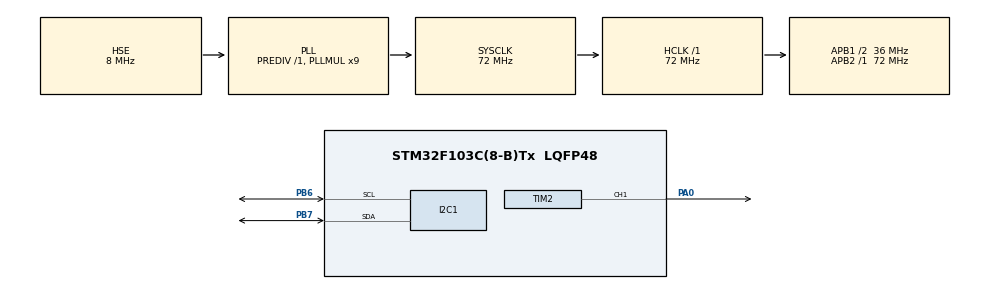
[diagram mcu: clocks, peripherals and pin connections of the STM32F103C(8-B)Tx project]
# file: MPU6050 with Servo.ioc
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Mcu.Family=STM32F1
Mcu.Name=STM32F103C(8-B)Tx
Mcu.Package=LQFP48
NVIC.PriorityGroup=NVIC_PRIORITYGROUP_4
NVIC.TIM1_UP_IRQn=true\:0\:0\:false\:false\:true\:true\:true\:true
NVIC.TIM2_IRQn=true\:0\:0\:false\:false\:true\:true\:true\:true
PA0-WKUP.Signal=S_TIM2_CH1_ETR
PA13.Mode=Serial_Wire
PA13.Signal=SYS_JTMS-SWDIO
PA14.Mode=Serial_Wire
PA14.Signal=SYS_JTCK-SWCLK
PB6.Mode=I2C
PB6.Signal=I2C1_SCL
PB7.Mode=I2C
PB7.Signal=I2C1_SDA
PD0-OSC_IN.Mode=HSE-External-Oscillator
PD0-OSC_IN.Signal=RCC_OSC_IN
PD1-OSC_OUT.Mode=HSE-External-Oscillator
PD1-OSC_OUT.Signal=RCC_OSC_OUT
ProjectManager.HeapSize=0x200
ProjectManager.StackSize=0x400
ProjectManager.TargetToolchain=MDK-ARM V5.32
RCC.AHBFreq_Value=72000000
RCC.APB1CLKDivider=RCC_HCLK_DIV2
RCC.APB1Freq_Value=36000000
RCC.APB1TimFreq_Value=72000000
RCC.APB2Freq_Value=72000000
RCC.APB2TimFreq_Value=72000000
RCC.HCLKFreq_Value=72000000
RCC.PLLMUL=RCC_PLL_MUL9
RCC.PLLSourceVirtual=RCC_PLLSOURCE_HSE
RCC.SYSCLKFreq_VALUE=72000000
RCC.SYSCLKSource=RCC_SYSCLKSOURCE_PLLCLK
RCC.USBFreq_Value=72000000
SH.S_TIM2_CH1_ETR.0=TIM2_CH1,PWM Generation1 CH1
TIM1.AutoReloadPreload=TIM_AUTORELOAD_PRELOAD_ENABLE
TIM1.Period=1999
TIM1.Prescaler=35999
TIM2.AutoReloadPreload=TIM_AUTORELOAD_PRELOAD_ENABLE
TIM2.Channel-PWM\ Generation1\ CH1=TIM_CHANNEL_1
TIM2.Period=799
TIM2.Prescaler=1799
VP_TIM1_VS_ClockSourceINT.Mode=Internal
board=custom

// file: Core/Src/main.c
/* USER CODE BEGIN Header */
/**
  ******************************************************************************
  * @file           : main.c
  * @brief          : Main program body
  ******************************************************************************
  * @attention
  *
  * Copyright (c) 2023 STMicroelectronics.
  * All rights reserved.
  *
  * This software is licensed under terms that can be found in the LICENSE file
  * in the root directory of this software component.
  * If no LICENSE file comes with this software, it is provided AS-IS.
  *
  ******************************************************************************
  */
/* USER CODE END Header */
#include "main.h"

/* USER CODE BEGIN Includes */
#include "sd_hal_mpu6050.h"
#include "stdint.h"
/* USER CODE END Includes */

/* USER CODE BEGIN PM */
void Servo_Angle(int angle);
void Servo_Angle2(int angle);
void MPU6050(I2C_HandleTypeDef *hi2c, SD_MPU6050 *mpu);
/* USER CODE END PM */

I2C_HandleTypeDef hi2c1;

TIM_HandleTypeDef htim1;
TIM_HandleTypeDef htim2;

/* USER CODE BEGIN PV */
SD_MPU6050 mpu1;

/* USER CODE END PV */

void SystemClock_Config(void);
static void MX_GPIO_Init(void);
static void MX_TIM1_Init(void);
static void MX_I2C1_Init(void);
static void MX_TIM2_Init(void);

/* USER CODE BEGIN 0 */
int counter = 0;
int G_angle =0;
float temp;
		int16_t a_x =0;
		int16_t a_y =0;
		int16_t a_z =0;
		int16_t Gyroscope_X = 0;
		int16_t Gyroscope_Y = 0;
		int16_t Gyroscope_Z = 0;
/* USER CODE END 0 */

int main(void)
{

  /* MCU Configuration--------------------------------------------------------*/

  /* Reset of all peripherals, Initializes the Flash interface and the Systick. */
  HAL_Init();

  /* Configure the system clock */
  SystemClock_Config();

  /* Initialize all configured peripherals */
  MX_GPIO_Init();
  MX_TIM1_Init();
  MX_I2C1_Init();
  MX_TIM2_Init();
  /* USER CODE BEGIN 2 */
	HAL_TIM_Base_Start_IT(&htim1);
	HAL_TIM_PWM_Start(&htim2,TIM_CHANNEL_1);
  /* USER CODE END 2 */

  /* Infinite loop */
  while (1)
  {

    /* USER CODE BEGIN 3 */
		if(counter%2 ==0)
		{MPU6050(&hi2c1,&mpu1);
		}

		G_angle = (a_x+20000)/300+9;
		HAL_TIM_PWM_Start(&htim2, TIM_CHANNEL_1);
		htim2.Instance -> CCR1 = G_angle;
		//Servo_Angle(G_angle);

		//Servo tim Prescaller = 1799, Counter = 799;
		//timer tim Prescaller = 35999, Counter = 1999;

  }
  /* USER CODE END 3 */
}

void SystemClock_Config(void)
{
  RCC_OscInitTypeDef RCC_OscInitStruct = {0};
  RCC_ClkInitTypeDef RCC_ClkInitStruct = {0};

  /** Initializes the RCC Oscillators according to the specified parameters
  * in the RCC_OscInitTypeDef structure.
  */
  RCC_OscInitStruct.OscillatorType = RCC_OSCILLATORTYPE_HSE;
  RCC_OscInitStruct.HSEState = RCC_HSE_ON;
  RCC_OscInitStruct.HSEPredivValue = RCC_HSE_PREDIV_DIV1;
  RCC_OscInitStruct.HSIState = RCC_HSI_ON;
  RCC_OscInitStruct.PLL.PLLState = RCC_PLL_ON;
  RCC_OscInitStruct.PLL.PLLSource = RCC_PLLSOURCE_HSE;
  RCC_OscInitStruct.PLL.PLLMUL = RCC_PLL_MUL9;
  if (HAL_RCC_OscConfig(&RCC_OscInitStruct) != HAL_OK)
  {
    Error_Handler();
  }

  /** Initializes the CPU, AHB and APB buses clocks
  */
  RCC_ClkInitStruct.ClockType = RCC_CLOCKTYPE_HCLK|RCC_CLOCKTYPE_SYSCLK
                              |RCC_CLOCKTYPE_PCLK1|RCC_CLOCKTYPE_PCLK2;
  RCC_ClkInitStruct.SYSCLKSource = RCC_SYSCLKSOURCE_PLLCLK;
  RCC_ClkInitStruct.AHBCLKDivider = RCC_SYSCLK_DIV1;
  RCC_ClkInitStruct.APB1CLKDivider = RCC_HCLK_DIV2;
  RCC_ClkInitStruct.APB2CLKDivider = RCC_HCLK_DIV1;

  if (HAL_RCC_ClockConfig(&RCC_ClkInitStruct, FLASH_LATENCY_2) != HAL_OK)
  {
    Error_Handler();
  }
}

static void MX_I2C1_Init(void)
{

  hi2c1.Instance = I2C1;
  hi2c1.Init.ClockSpeed = 100000;
  hi2c1.Init.DutyCycle = I2C_DUTYCYCLE_2;
  hi2c1.Init.OwnAddress1 = 0;
  hi2c1.Init.AddressingMode = I2C_ADDRESSINGMODE_7BIT;
  hi2c1.Init.DualAddressMode = I2C_DUALADDRESS_DISABLE;
  hi2c1.Init.OwnAddress2 = 0;
  hi2c1.Init.GeneralCallMode = I2C_GENERALCALL_DISABLE;
  hi2c1.Init.NoStretchMode = I2C_NOSTRETCH_DISABLE;
  if (HAL_I2C_Init(&hi2c1) != HAL_OK)
  {
    Error_Handler();
  }

}

static void MX_TIM1_Init(void)
{

  TIM_ClockConfigTypeDef sClockSourceConfig = {0};
  TIM_MasterConfigTypeDef sMasterConfig = {0};

  htim1.Instance = TIM1;
  htim1.Init.Prescaler = 35999;
  htim1.Init.CounterMode = TIM_COUNTERMODE_UP;
  htim1.Init.Period = 1999;
  htim1.Init.ClockDivision = TIM_CLOCKDIVISION_DIV1;
  htim1.Init.RepetitionCounter = 0;
  htim1.Init.AutoReloadPreload = TIM_AUTORELOAD_PRELOAD_ENABLE;
  if (HAL_TIM_Base_Init(&htim1) != HAL_OK)
  {
    Error_Handler();
  }
  sClockSourceConfig.ClockSource = TIM_CLOCKSOURCE_INTERNAL;
  if (HAL_TIM_ConfigClockSource(&htim1, &sClockSourceConfig) != HAL_OK)
  {
    Error_Handler();
  }
  sMasterConfig.MasterOutputTrigger = TIM_TRGO_RESET;
  sMasterConfig.MasterSlaveMode = TIM_MASTERSLAVEMODE_DISABLE;
  if (HAL_TIMEx_MasterConfigSynchronization(&htim1, &sMasterConfig) != HAL_OK)
  {
    Error_Handler();
  }

}

static void MX_TIM2_Init(void)
{

  TIM_MasterConfigTypeDef sMasterConfig = {0};
  TIM_OC_InitTypeDef sConfigOC = {0};

  htim2.Instance = TIM2;
  htim2.Init.Prescaler = 1799;
  htim2.Init.CounterMode = TIM_COUNTERMODE_UP;
  htim2.Init.Period = 799;
  htim2.Init.ClockDivision = TIM_CLOCKDIVISION_DIV1;
  htim2.Init.AutoReloadPreload = TIM_AUTORELOAD_PRELOAD_ENABLE;
  if (HAL_TIM_PWM_Init(&htim2) != HAL_OK)
  {
    Error_Handler();
  }
  sMasterConfig.MasterOutputTrigger = TIM_TRGO_RESET;
  sMasterConfig.MasterSlaveMode = TIM_MASTERSLAVEMODE_DISABLE;
  if (HAL_TIMEx_MasterConfigSynchronization(&htim2, &sMasterConfig) != HAL_OK)
  {
    Error_Handler();
  }
  sConfigOC.OCMode = TIM_OCMODE_PWM1;
  sConfigOC.Pulse = 0;
  sConfigOC.OCPolarity = TIM_OCPOLARITY_HIGH;
  sConfigOC.OCFastMode = TIM_OCFAST_DISABLE;
  if (HAL_TIM_PWM_ConfigChannel(&htim2, &sConfigOC, TIM_CHANNEL_1) != HAL_OK)
  {
    Error_Handler();
  }
  HAL_TIM_MspPostInit(&htim2);

}

static void MX_GPIO_Init(void)
{

  /* GPIO Ports Clock Enable */
  __HAL_RCC_GPIOD_CLK_ENABLE();
  __HAL_RCC_GPIOA_CLK_ENABLE();
  __HAL_RCC_GPIOB_CLK_ENABLE();

}

/* USER CODE BEGIN 4 */
void Servo_Angle(int angle)
{
	int value;

	if(angle<0)
		value=0;
	if(angle > 180)
		value = 125;

	value = (int)(angle *100/180+25);

	htim2.Instance -> CCR1 = value;
	//return value;

}
void MPU6050(I2C_HandleTypeDef *hi2c, SD_MPU6050 *mpu)
{
	  int result = SD_MPU6050_Init(&hi2c1,&mpu1,SD_MPU6050_Device_0,SD_MPU6050_Accelerometer_16G,SD_MPU6050_Gyroscope_2000s);
	  HAL_Delay(50);
    /* USER CODE END WHILE */

    /* USER CODE BEGIN 3 */
	  SD_MPU6050_ReadAccelerometer(&hi2c1,&mpu1);
	  a_x = mpu1.Accelerometer_X;
	  a_y = mpu1.Accelerometer_Y;
	  a_z = mpu1.Accelerometer_Z;

		SD_MPU6050_ReadTemperature(&hi2c1,&mpu1);
		temp = mpu1.Temperature;

		SD_MPU6050_ReadGyroscope(&hi2c1,&mpu1);
		Gyroscope_X = mpu1.Gyroscope_X;
		Gyroscope_Y = mpu1.Gyroscope_Y;
		Gyroscope_Z = mpu1.Gyroscope_Z;
}
void HAL_TIM_PeriodElapsedCallback(TIM_HandleTypeDef *htim)
{
	if(htim -> Instance == TIM1)
		counter ++;

}
/* USER CODE END 4 */

void Error_Handler(void)
{
  __disable_irq();
  while (1)
  {
  }
}
